# R7FA8M1AH register map
Vendor: Renesas; Series: RA8; File version: 1.2
CPU: CM85 r0p0, little endian, MPU, FPU, VTOR, 4 interrupt priority bits
Registers are 32-bit, read-write, reset 0x0 unless marked. A register's access mark holds for its fields unless they carry their own. Offsets are from the block's base; [hi:lo] are bit positions; {n}, {i} and the like mark numbered series; 'fields as' and 'values as' point back to an identical list.

## GPT320 (part 1 of 2) — General PWM 32-bit Timer 0
Base 0x40322000
Same registers: GPT321 0x40322100, GPT322 0x40322200, GPT323 0x40322300, GPT324 0x40322400, GPT325 0x40322500, GPT326 0x40322600, GPT327 0x40322700, GPT168 0x40322800, GPT169 0x40322900, GPT1610 0x40322A00, GPT1611 0x40322B00, GPT1612 0x40322C00, GPT1613 0x40322D00, GPT{n}_NS {0x5030E000+0x100*n} (n=320..327), GPT168_NS 0x50322800, GPT169_NS 0x50322900, GPT1610_NS 0x50322A00, GPT1611_NS 0x50322B00, GPT1612_NS 0x50322C00, GPT1613_NS 0x50322D00
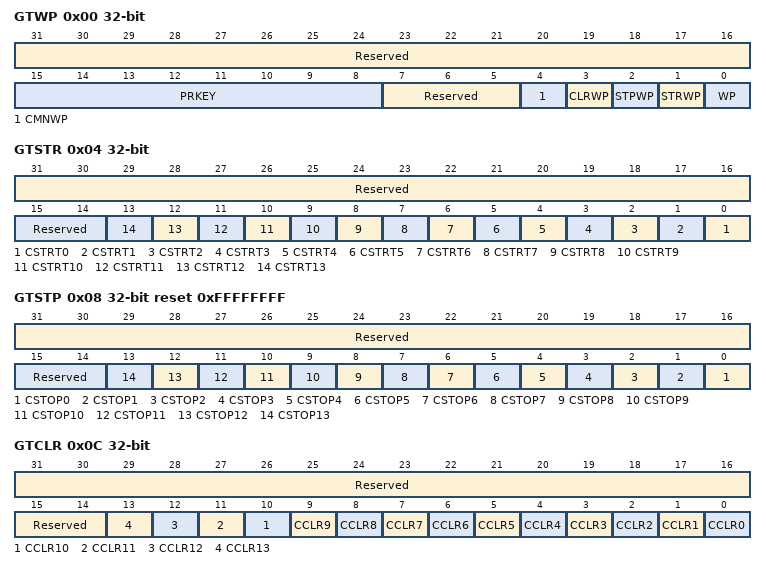
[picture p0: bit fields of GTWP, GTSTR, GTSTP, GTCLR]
0x00 GTWP — General PWM Timer Write-Protection Register
  [31:16] Reserved — These bits are read as 0000000000000000. The write value should be 0000000000000000.
  [15:8] PRKEY wo — GTWP Key Code
    165=Written to these bits, the WP bits write is permitted; other=others (The WP bits write is not permitted.)
  [7:5] Reserved — These bits are read as 000. The write value should be 000.
  [4] CMNWP — Common Register Write Disabled
    0=Write to the register is enabled; 1=Write to the register is disabled
  [3] CLRWP — GTCLR.CCLR Bit Write Disabled
    0=Write to the bit is enabled; 1=Write to the bit is disabled
  [2] STPWP — GTSTP.CSTOP Bit Write Disabled
    values as CLRWP
  [1] STRWP — GTSTR.CSTRT Bit Write Disabled
    values as CLRWP
  [0] WP — Register Write Disable
    0=Enable writes to the register; 1=Disable writes to the register
0x04 GTSTR — General PWM Timer Software Start Register
  [31:16] Reserved — These bits are read as 0000000000000000. The write value should be 0000000000000000.
  [15:14] Reserved — These bits are read as 00. The write value should be 00.
  [n] CSTRT{n} (n=0..13) — Channel {n} GTCNT Count StartRead data shows each channel's counter status (GTCR.CST bit). 0 means counter stop. 1 means counter running.
    0=No effect (write) / counter stop (read); 1=GTCNT counter starts (write) / Counter running (read)
0x08 GTSTP reset 0xFFFFFFFF — General PWM Timer Software Stop Register
  [31:16] Reserved — These bits are read as 1111111111111111. The write value should be 1111111111111111.
  [15:14] Reserved — These bits are read as 11. The write value should be 11.
  [n] CSTOP{n} (n=0..13) — Channel {n} GTCNT Count StopRead data shows each channel's counter status (GTCR.CST bit). 0 means counter runnning. 1 means counter stop.
    0=No effect (write) / counter running (read); 1=GTCNT counter stops (write) / Counter stop (read)
0x0C GTCLR wo — General PWM Timer Software Clear Register
  [31:14] Reserved — The write value should be 000000000000000000.
  [n] CCLR{n} (n=0..13) — Channel {n} GTCNT Count Clear
    0=No effect; 1=GTCNT counter clears
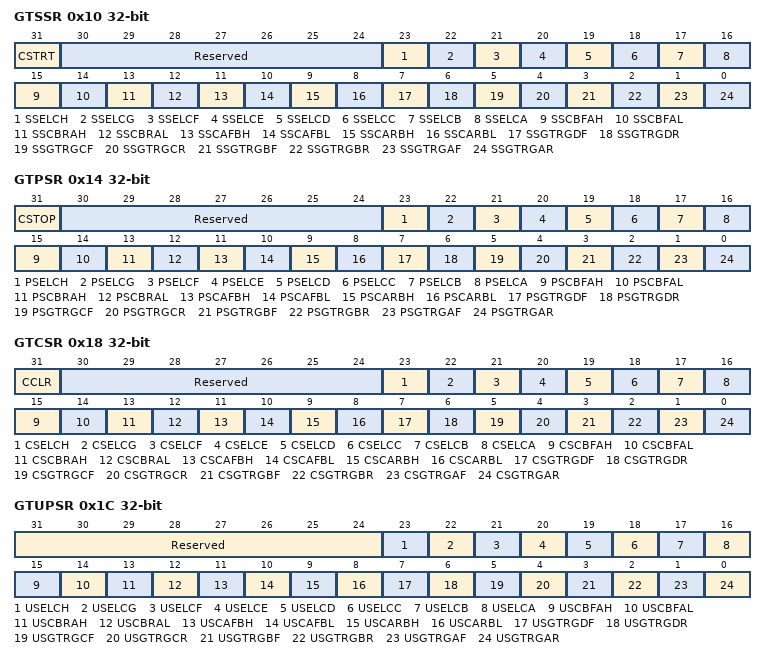
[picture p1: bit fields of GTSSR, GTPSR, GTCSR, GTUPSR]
0x10 GTSSR — General PWM Timer Start Source Select Register
  [31] CSTRT — Software Source Counter Start Enable
    0=Disable counter start by the GTSTR register; 1=Enable counter start by the GTSTR register
  [30:24] Reserved — These bits are read as 0000000. The write value should be 0000000.
  [23] SSELCH — ELC_GPTH Event Source Counter Start Enable
    0=Disable counter start on ELC_GPTH input; 1=Enable counter start on ELC_GPTH input
  [22] SSELCG — ELC_GPTG Event Source Counter Start Enable
    0=Disable counter start on ELC_GPTG input; 1=Enable counter start on ELC_GPTG input
  [21] SSELCF — ELC_GPTF Event Source Counter Start Enable
    0=Disable counter start on ELC_GPTF input; 1=Enable counter start on ELC_GPTF input
  [20] SSELCE — ELC_GPTE Event Source Counter Start Enable
    0=Disable counter start on ELC_GPTE input; 1=Enable counter start on ELC_GPTE input
  [19] SSELCD — ELC_GPTD Event Source Counter Start Enable
    0=Disable counter start on ELC_GPTD input; 1=Enable counter start on ELC_GPTD input
  [18] SSELCC — ELC_GPTC Event Source Counter Start Enable
    0=Disable counter start on ELC_GPTC input; 1=Enable counter start on ELC_GPTC input
  [17] SSELCB — ELC_GPTB Event Source Counter Start Enable
    0=Disable counter start on ELC_GPTB input; 1=Enable counter start on ELC_GPTB input
  [16] SSELCA — ELC_GPTA Event Source Counter Start Enable
    0=Disable counter start on ELC_GPTA input; 1=Enable counter start on ELC_GPTA input
  [15] SSCBFAH — GTIOCB Pin Falling Input during GTIOCA Value High Source Counter Start Enable
    0=Disable counter start on the falling edge of GTIOCB input when GTIOCA input is 1; 1=Enable counter start on the falling edge of GTIOCB input when GTIOCA input is 1
  [14] SSCBFAL — GTIOCB Pin Falling Input during GTIOCA Value Low Source Counter Start Enable
    0=Disable counter start on the falling edge of GTIOCB input when GTIOCA input is 0; 1=Enable counter start on the falling edge of GTIOCB input when GTIOCA input is 0
  [13] SSCBRAH — GTIOCB Pin Rising Input during GTIOCA Value High Source Counter Start Enable
    0=Disable counter start on the rising edge of GTIOCB input when GTIOCA input is 1; 1=Enable counter start on the rising edge of GTIOCB input when GTIOCA input is 1
  [12] SSCBRAL — GTIOCB Pin Rising Input during GTIOCA Value Low Source Counter Start Enable
    0=Disable counter start on the rising edge of GTIOCB input when GTIOCA input is 0; 1=Enable counter start on the rising edge of GTIOCB input when GTIOCA input is 0
  [11] SSCAFBH — GTIOCA Pin Falling Input during GTIOCB Value High Source Counter Start Enable
    0=Disable counter start on the falling edge of GTIOCA input when GTIOCB input is 1; 1=Enable counter start on the falling edge of GTIOCA input when GTIOCB input is 1
  [10] SSCAFBL — GTIOCA Pin Falling Input during GTIOCB Value Low Source Counter Start Enable
    0=Disable counter start on the falling edge of GTIOCA input when GTIOCB input is 0; 1=Enable counter start on the falling edge of GTIOCA input when GTIOCB input is 0
  [9] SSCARBH — GTIOCA Pin Rising Input during GTIOCB Value High Source Counter Start Enable
    0=Disable counter start on the rising edge of GTIOCA input when GTIOCB input is 1; 1=Enable counter start on the rising edge of GTIOCA input when GTIOCB input is 1
  [8] SSCARBL — GTIOCA Pin Rising Input during GTIOCB Value Low Source Counter Start Enable
    0=Disable counter start on the rising edge of GTIOCA input when GTIOCB input is 0; 1=Enable counter start on the rising edge of GTIOCA input when GTIOCB input is 0
  [7] SSGTRGDF — GTETRGD Pin Falling Input Source Counter Start Enable
    0=Disable counter start on the falling edge of GTETRGD input; 1=Enable counter start on the falling edge of GTETRGD input
  [6] SSGTRGDR — GTETRGD Pin Rising Input Source Counter Start Enable
    0=Disable counter start on the rising edge of GTETRGD input; 1=Enable counter start on the rising edge of GTETRGD input
  [5] SSGTRGCF — GTETRGC Pin Falling Input Source Counter Start Enable
    0=Disable counter start on the falling edge of GTETRGC input; 1=Enable counter start on the falling edge of GTETRGC input
  [4] SSGTRGCR — GTETRGC Pin Rising Input Source Counter Start Enable
    0=Disable counter start on the rising edge of GTETRGC input; 1=Enable counter start on the rising edge of GTETRGC input
  [3] SSGTRGBF — GTETRGB Pin Falling Input Source Counter Start Enable
    0=Disable counter start on the falling edge of GTETRGB input; 1=Enable counter start on the falling edge of GTETRGB input
  [2] SSGTRGBR — GTETRGB Pin Rising Input Source Counter Start Enable
    0=Disable counter start on the rising edge of GTETRGB input; 1=Enable counter start on the rising edge of GTETRGB input
  [1] SSGTRGAF — GTETRGA Pin Falling Input Source Counter Start Enable
    0=Disable counter start on the falling edge of GTETRGA input; 1=Enable counter start on the falling edge of GTETRGA input
  [0] SSGTRGAR — GTETRGA Pin Rising Input Source Counter Start Enable
    0=Disable counter start on the rising edge of GTETRGA input; 1=Enable counter start on the rising edge of GTETRGA input
0x14 GTPSR — General PWM Timer Stop Source Select Register
  [31] CSTOP — Software Source Counter Stop Enable
    0=Disable counter stop by the GTSTP register; 1=Enable counter stop by the GTSTP register
  [30:24] Reserved — These bits are read as 0000000. The write value should be 0000000.
  [23] PSELCH — ELC_GPTH Event Source Counter Stop Enable
    0=Disable counter stop on ELC_GPTH input; 1=Enable counter stop on ELC_GPTH input
  [22] PSELCG — ELC_GPTG Event Source Counter Stop Enable
    0=Disable counter stop on ELC_GPTG input; 1=Enable counter stop on ELC_GPTG input
  [21] PSELCF — ELC_GPTF Event Source Counter Stop Enable
    0=Disable counter stop on ELC_GPTF input; 1=Enable counter stop on ELC_GPTF input
  [20] PSELCE — ELC_GPTE Event Source Counter Stop Enable
    0=Disable counter stop on ELC_GPTE input; 1=Enable counter stop on ELC_GPTE input
  [19] PSELCD — ELC_GPTD Event Source Counter Stop Enable
    0=Disable counter stop on ELC_GPTD input; 1=Enable counter stop on ELC_GPTD input
  [18] PSELCC — ELC_GPTC Event Source Counter Stop Enable
    0=Disable counter stop on ELC_GPTC input; 1=Enable counter stop on ELC_GPTC input
  [17] PSELCB — ELC_GPTB Event Source Counter Stop Enable
    0=Disable counter stop on ELC_GPTB input; 1=Enable counter stop on ELC_GPTB input
  [16] PSELCA — ELC_GPTA Event Source Counter Stop Enable
    0=Disable counter stop on ELC_GPTA input; 1=Enable counter stop on ELC_GPTA input
  [15] PSCBFAH — GTIOCB Pin Falling Input during GTIOCA Value High Source Counter Stop Enable
    0=Disable counter stop on the falling edge of GTIOCB input when GTIOCA input is 1; 1=Enable counter stop on the falling edge of GTIOCB input when GTIOCA input is 1
  [14] PSCBFAL — GTIOCB Pin Falling Input during GTIOCA Value Low Source Counter Stop Enable
    0=Disable counter stop on the falling edge of GTIOCB input when GTIOCA input is 0; 1=Enable counter stop on the falling edge of GTIOCB input when GTIOCA input is 0
  [13] PSCBRAH — GTIOCB Pin Rising Input during GTIOCA Value High Source Counter Stop Enable
    0=Disable counter stop on the rising edge of GTIOCB input when GTIOCA input is 1; 1=Enable counter stop on the rising edge of GTIOCB input when GTIOCA input is 1
  [12] PSCBRAL — GTIOCB Pin Rising Input during GTIOCA Value Low Source Counter Stop Enable
    0=Disable counter stop on the rising edge of GTIOCB input when GTIOCA input is 0; 1=Enable counter stop on the rising edge of GTIOCB input when GTIOCA input is 0
  [11] PSCAFBH — GTIOCA Pin Falling Input during GTIOCB Value High Source Counter Stop Enable
    0=Disable counter stop on the falling edge of GTIOCA input when GTIOCB input is 1; 1=Enable counter stop on the falling edge of GTIOCA input when GTIOCB input is 1
  [10] PSCAFBL — GTIOCA Pin Falling Input during GTIOCB Value Low Source Counter Stop Enable
    0=Disable counter stop on the falling edge of GTIOCA input when GTIOCB input is 0; 1=Enable counter stop on the falling edge of GTIOCA input when GTIOCB input is 0
  [9] PSCARBH — GTIOCA Pin Rising Input during GTIOCB Value High Source Counter Stop Enable
    0=Disable counter stop on the rising edge of GTIOCA input when GTIOCB input is 1; 1=Enable counter stop on the rising edge of GTIOCA input when GTIOCB input is 1
  [8] PSCARBL — GTIOCA Pin Rising Input during GTIOCB Value Low Source Counter Stop Enable
    0=Disable counter stop on the rising edge of GTIOCA input when GTIOCB input is 0; 1=Enable counter stop on the rising edge of GTIOCA input when GTIOCB input is 0
  [7] PSGTRGDF — GTETRGD Pin Falling Input Source Counter Stop Enable
    0=Disable counter stop on the falling edge of GTETRGD input; 1=Enable counter stop on the falling edge of GTETRGD input
  [6] PSGTRGDR — GTETRGD Pin Rising Input Source Counter Stop Enable
    0=Disable counter stop on the rising edge of GTETRGD input; 1=Enable counter stop on the rising edge of GTETRGD input
  [5] PSGTRGCF — GTETRGC Pin Falling Input Source Counter Stop Enable
    0=Disable counter stop on the falling edge of GTETRGC input; 1=Enable counter stop on the falling edge of GTETRGC input
  [4] PSGTRGCR — GTETRGC Pin Rising Input Source Counter Stop Enable
    0=Disable counter stop on the rising edge of GTETRGC input; 1=Enable counter stop on the rising edge of GTETRGC input
  [3] PSGTRGBF — GTETRGB Pin Falling Input Source Counter Stop Enable
    0=Disable counter stop on the falling edge of GTETRGB input; 1=Enable counter stop on the falling edge of GTETRGB input
  [2] PSGTRGBR — GTETRGB Pin Rising Input Source Counter Stop Enable
    0=Disable counter stop on the rising edge of GTETRGB input; 1=Enable counter stop on the rising edge of GTETRGB input
  [1] PSGTRGAF — GTETRGA Pin Falling Input Source Counter Stop Enable
    0=Disable counter stop on the falling edge of GTETRGA input; 1=Enable counter stop on the falling edge of GTETRGA input
  [0] PSGTRGAR — GTETRGA Pin Rising Input Source Counter Stop Enable
    0=Disable counter stop on the rising edge of GTETRGA input; 1=Enable counter stop on the rising edge of GTETRGA input
0x18 GTCSR — General PWM Timer Clear Source Select Register
  [31] CCLR — Software Source Counter Clear Enable
    0=Disable counter clear by the GTCLR register; 1=Enable counter clear by the GTCLR register
  [30:24] Reserved — These bits are read as 0000000. The write value should be 0000000.
  [23] CSELCH — ELC_GPTH Event Source Counter Clear Enable
    0=Disable counter clear on ELC_GPTH input; 1=Enable counter clear on ELC_GPTH input
  [22] CSELCG — ELC_GPTG Event Source Counter Clear Enable
    0=Disable counter clear on ELC_GPTG input; 1=Enable counter clear on ELC_GPTG input
  [21] CSELCF — ELC_GPTF Event Source Counter Clear Enable
    0=Disable counter clear on ELC_GPTF input; 1=Enable counter clear on ELC_GPTF input
  [20] CSELCE — ELC_GPTE Event Source Counter Clear Enable
    0=Disable counter clear on ELC_GPTE input; 1=Enable counter clear on ELC_GPTE input
  [19] CSELCD — ELC_GPTD Event Source Counter Clear Enable
    0=Disable counter clear on ELC_GPTD input; 1=Enable counter clear on ELC_GPTD input
  [18] CSELCC — ELC_GPTC Event Source Counter Clear Enable
    0=Disable counter clear on ELC_GPTC input; 1=Enable counter clear on ELC_GPTC input
  [17] CSELCB — ELC_GPTB Event Source Counter Clear Enable
    0=Disable counter clear on ELC_GPTB input; 1=Enable counter clear on ELC_GPTB input
  [16] CSELCA — ELC_GPTA Event Source Counter Clear Enable
    0=Disable counter clear on ELC_GPTA input; 1=Enable counter clear on ELC_GPTA input
  [15] CSCBFAH — GTIOCB Pin Falling Input during GTIOCA Value High Source Counter Clear Enable
    0=Disable counter clear on the falling edge of GTIOCB input when GTIOCA input is 1; 1=Enable counter clear on the falling edge of GTIOCB input when GTIOCA input is 1
  [14] CSCBFAL — GTIOCB Pin Falling Input during GTIOCA Value Low Source Counter Clear Enable
    0=Disable counter clear on the falling edge of GTIOCB input when GTIOCA input is 0; 1=Enable counter clear on the falling edge of GTIOCB input when GTIOCA input is 0
  [13] CSCBRAH — GTIOCB Pin Rising Input during GTIOCA Value High Source Counter Clear Enable
    0=Disable counter clear on the rising edge of GTIOCB input when GTIOCA input is 1; 1=Enable counter clear on the rising edge of GTIOCB input when GTIOCA input is 1
  [12] CSCBRAL — GTIOCB Pin Rising Input during GTIOCA Value Low Source Counter Clear Enable
    0=Disable counter clear on the rising edge of GTIOCB input when GTIOCA input is 0; 1=Enable counter clear on the rising edge of GTIOCB input when GTIOCA input is 0
  [11] CSCAFBH — GTIOCA Pin Falling Input during GTIOCB Value High Source Counter Clear Enable
    0=Disable counter clear on the falling edge of GTIOCA input when GTIOCB input is 1; 1=Enable counter clear on the falling edge of GTIOCA input when GTIOCB input is 1
  [10] CSCAFBL — GTIOCA Pin Falling Input during GTIOCB Value Low Source Counter Clear Enable
    0=Disable counter clear on the falling edge of GTIOCA input when GTIOCB input is 0; 1=Enable counter clear on the falling edge of GTIOCA input when GTIOCB input is 0
  [9] CSCARBH — GTIOCA Pin Rising Input during GTIOCB Value High Source Counter Clear Enable
    0=Disable counter clear on the rising edge of GTIOCA input when GTIOCB input is 1; 1=Enable counter clear on the rising edge of GTIOCA input when GTIOCB input is 1
  [8] CSCARBL — GTIOCA Pin Rising Input during GTIOCB Value Low Source Counter Clear Enable
    0=Disable counter clear on the rising edge of GTIOCA input when GTIOCB input is 0; 1=Enable counter clear on the rising edge of GTIOCA input when GTIOCB input is 0
  [7] CSGTRGDF — GTETRGD Pin Falling Input Source Counter Clear Enable
    0=Disable counter clear on the falling edge of GTETRGD input; 1=Enable counter clear on the falling edge of GTETRGD input
  [6] CSGTRGDR — GTETRGD Pin Rising Input Source Counter Clear Enable
    0=Disable counter clear on the rising edge of GTETRGD input; 1=Enable counter clear on the rising edge of GTETRGD input
  [5] CSGTRGCF — GTETRGC Pin Falling Input Source Counter Clear Enable
    0=Disable counter clear on the falling edge of GTETRGC input; 1=Enable counter clear on the falling edge of GTETRGC input
  [4] CSGTRGCR — GTETRGC Pin Rising Input Source Counter Clear Enable
    0=Disable counter clear on the rising edge of GTETRGC input; 1=Enable counter clear on the rising edge of GTETRGC input
  [3] CSGTRGBF — GTETRGB Pin Falling Input Source Counter Clear Enable
    0=Disable counter clear on the falling edge of GTETRGB input; 1=Enable counter clear on the falling edge of GTETRGB input
  [2] CSGTRGBR — GTETRGB Pin Rising Input Source Counter Clear Enable
    0=Disable counter clear on the rising edge of GTETRGB input; 1=Enable counter clear on the rising edge of GTETRGB input
  [1] CSGTRGAF — GTETRGA Pin Falling Input Source Counter Clear Enable
    0=Disable counter clear on the falling edge of GTETRGA input; 1=Enable counter clear on the falling edge of GTETRGA input
  [0] CSGTRGAR — GTETRGA Pin Rising Input Source Counter Clear Enable
    0=Disable counter clear on the rising edge of GTETRGA input; 1=Enable counter clear on the rising edge of GTETRGA input
0x1C GTUPSR — General PWM Timer Up Count Source Select Register
  [31:24] Reserved — These bits are read as 00000000. The write value should be 00000000.
  [23] USELCH — ELC_GPTH Event Source Counter Count Up Enable
    0=Disable counter count up on ELC_GPTH input; 1=Enable counter count up on ELC_GPTH input
  [22] USELCG — ELC_GPTG Event Source Counter Count Up Enable
    0=Disable counter count up on ELC_GPTG input; 1=Enable counter count up on ELC_GPTG input
  [21] USELCF — ELC_GPTF Event Source Counter Count Up Enable
    0=Disable counter count up on ELC_GPTF input; 1=Enable counter count up on ELC_GPTF input
  [20] USELCE — ELC_GPTE Event Source Counter Count Up Enable
    0=Disable counter count up on ELC_GPTE input; 1=Enable counter count up on ELC_GPTE input.put
  [19] USELCD — ELC_GPTD Event Source Counter Count Up Enable
    0=Disable counter count up on ELC_GPTD input; 1=Enable counter count up on ELC_GPTD input
  [18] USELCC — ELC_GPTC Event Source Counter Count Up Enable
    0=Disable counter count up on ELC_GPTC input; 1=Enable counter count up on ELC_GPTC input
  [17] USELCB — ELC_GPTB Event Source Counter Count Up Enable
    0=Disable counter count up on ELC_GPTB input; 1=Enable counter count up on ELC_GPTB input
  [16] USELCA — ELC_GPTA Event Source Counter Count Up Enable
    0=Disable counter count up on ELC_GPTA input; 1=Enable counter count up on ELC_GPTA input
  [15] USCBFAH — GTIOCB Pin Falling Input during GTIOCA Value High Source Counter Count Up Enable
    0=Disable counter count up on the falling edge of GTIOCB input when GTIOCA input is 1; 1=Enable counter count up on the falling edge of GTIOCB input when GTIOCA input is 1
  [14] USCBFAL — GTIOCB Pin Falling Input during GTIOCA Value Low Source Counter Count Up Enable
    0=Disable counter count up on the falling edge of GTIOCB input when GTIOCA input is 0; 1=Enable counter count up on the falling edge of GTIOCB input when GTIOCA input is 0
  [13] USCBRAH — GTIOCB Pin Rising Input during GTIOCA Value High Source Counter Count Up Enable
    0=Disable counter count up on the rising edge of GTIOCB input when GTIOCA input is 1; 1=Enable counter count up on the rising edge of GTIOCB input when GTIOCA input is 1
  [12] USCBRAL — GTIOCB Pin Rising Input during GTIOCA Value Low Source Counter Count Up Enable
    0=Disable counter count up on the rising edge of GTIOCB input when GTIOCA input is 0; 1=Enable counter count up on the rising edge of GTIOCB input when GTIOCA input is 0
  [11] USCAFBH — GTIOCA Pin Falling Input during GTIOCB Value High Source Counter Count Up Enable
    0=Disable counter count up on the falling edge of GTIOCA input when GTIOCB input is 1; 1=Enable counter count up on the falling edge of GTIOCA input when GTIOCB input is 1
  [10] USCAFBL — GTIOCA Pin Falling Input during GTIOCB Value Low Source Counter Count Up Enable
    0=Disable counter count up on the falling edge of GTIOCA input when GTIOCB input is 0; 1=Enable counter count up on the falling edge of GTIOCA input when GTIOCB input is 0
  [9] USCARBH — GTIOCA Pin Rising Input during GTIOCB Value High Source Counter Count Up Enable
    0=Disable counter count up on the rising edge of GTIOCA input when GTIOCB input is 1; 1=Enable counter count up on the rising edge of GTIOCA input when GTIOCB input is 1
  [8] USCARBL — GTIOCA Pin Rising Input during GTIOCB Value Low Source Counter Count Up Enable
    0=Disable counter count up on the rising edge of GTIOCA input when GTIOCB input is 0; 1=Enable counter count up on the rising edge of GTIOCA input when GTIOCB input is 0
  [7] USGTRGDF — GTETRGD Pin Falling Input Source Counter Count Up Enable
    0=Disable counter count up on the falling edge of GTETRGD input; 1=Enable counter count up on the falling edge of GTETRGD input
  [6] USGTRGDR — GTETRGD Pin Rising Input Source Counter Count Up Enable
    0=Disable counter count up on the rising edge of GTETRGD input; 1=Enable counter count up on the rising edge of GTETRGD input
  [5] USGTRGCF — GTETRGC Pin Falling Input Source Counter Count Up Enable
    0=Disable counter count up on the falling edge of GTETRGC input; 1=Enable counter count up on the falling edge of GTETRGC input
  [4] USGTRGCR — GTETRGC Pin Rising Input Source Counter Count Up Enable
    0=Disable counter count up on the rising edge of GTETRGC input; 1=Enable counter count up on the rising edge of GTETRGC input
  [3] USGTRGBF — GTETRGB Pin Falling Input Source Counter Count Up Enable
    0=Disable counter count up on the falling edge of GTETRGB input; 1=Enable counter count up on the falling edge of GTETRGB input
  [2] USGTRGBR — GTETRGB Pin Rising Input Source Counter Count Up Enable
    0=Disable counter count up on the rising edge of GTETRGB input; 1=Enable counter count up on the rising edge of GTETRGB input
  [1] USGTRGAF — GTETRGA Pin Falling Input Source Counter Count Up Enable
    0=Disable counter count up on the falling edge of GTETRGA input; 1=Enable counter count up on the falling edge of GTETRGA input
  [0] USGTRGAR — GTETRGA Pin Rising Input Source Counter Count Up Enable
    0=Disable counter count up on the rising edge of GTETRGA input; 1=Enable counter count up on the rising edge of GTETRGA input
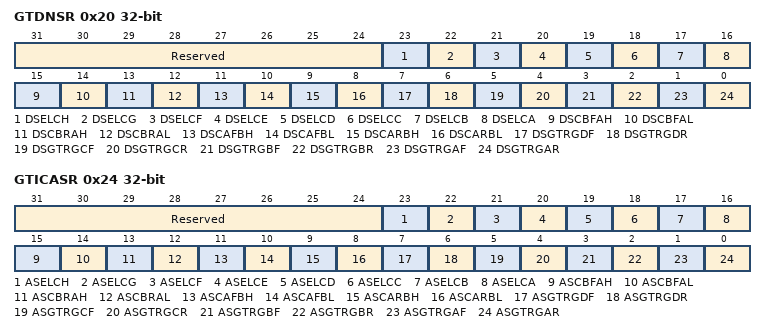
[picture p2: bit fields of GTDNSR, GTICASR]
0x20 GTDNSR — General PWM Timer Down Count Source Select Register
  [31:24] Reserved — These bits are read as 00000000. The write value should be 00000000.
  [23] DSELCH — ELC_GPTH Event Source Counter Count Down Enable
    0=Disable counter count down on ELC_GPTH input; 1=Enable counter count down on ELC_GPTH input
  [22] DSELCG — ELC_GPTG Event Source Counter Count Down Enable
    0=Disable counter count down on ELC_GPTG input; 1=Enable counter count down on ELC_GPTG input
  [21] DSELCF — ELC_GPTF Event Source Counter Count Down Enable
    0=Disable counter count down on ELC_GPTF input; 1=Enable counter count down on ELC_GPTF input
  [20] DSELCE — ELC_GPTE Event Source Counter Count Down Enable
    0=Disable counter count down on ELC_GPTE input; 1=Enable counter count down on ELC_GPTE input
  [19] DSELCD — ELC_GPTD Event Source Counter Count Down Enable
    0=Disable counter count down on ELC_GPTD input; 1=Enable counter count down on ELC_GPTD input
  [18] DSELCC — ELC_GPTC Event Source Counter Count Down Enable
    0=Disable counter count down on ELC_GPTC input; 1=Enable counter count down on ELC_GPTC input
  [17] DSELCB — ELC_GPTB Event Source Counter Count Down Enable
    0=Disable counter count down on ELC_GPTB input; 1=Enable counter count down on ELC_GPTB input
  [16] DSELCA — ELC_GPTA Event Source Counter Count Down Enable
    0=Disable counter count down on ELC_GPTA input; 1=Enable counter count down on ELC_GPTA input
  [15] DSCBFAH — GTIOCB Pin Falling Input during GTIOCA Value High Source Counter Count Down Enable
    0=Disable counter count down on the falling edge of GTIOCB input when GTIOCA input is 1; 1=Enable counter count down on the falling edge of GTIOCB input when GTIOCA input is 1
  [14] DSCBFAL — GTIOCB Pin Falling Input during GTIOCA Value Low Source Counter Count Down Enable
    0=Disable counter count down on the falling edge of GTIOCB input when GTIOCA input is 0; 1=Enable counter count down on the falling edge of GTIOCB input when GTIOCA input is 0
  [13] DSCBRAH — GTIOCB Pin Rising Input during GTIOCA Value High Source Counter Count Down Enable
    0=Disable counter count down on the rising edge of GTIOCB input when GTIOCA input is 1; 1=Enable counter count down on the rising edge of GTIOCB input when GTIOCA input is 1
  [12] DSCBRAL — GTIOCB Pin Rising Input during GTIOCA Value Low Source Counter Count Down Enable
    0=Disable counter count down on the rising edge of GTIOCB input when GTIOCA input is 0; 1=Enable counter count down on the rising edge of GTIOCB input when GTIOCA input is 0
  [11] DSCAFBH — GTIOCA Pin Falling Input during GTIOCB Value High Source Counter Count Down Enable
    0=Disable counter count down on the falling edge of GTIOCA input when GTIOCB input is 1; 1=Enable counter count down on the falling edge of GTIOCA input when GTIOCB input is 1
  [10] DSCAFBL — GTIOCA Pin Falling Input during GTIOCB Value Low Source Counter Count Down Enable
    0=Disable counter count down on the falling edge of GTIOCA input when GTIOCB input is 0; 1=Enable counter count down on the falling edge of GTIOCA input when GTIOCB input is 0
  [9] DSCARBH — GTIOCA Pin Rising Input during GTIOCB Value High Source Counter Count Down Enable
    0=Disable counter count down on the rising edge of GTIOCA input when GTIOCB input is 1; 1=Enable counter count down on the rising edge of GTIOCA input when GTIOCB input is 1
  [8] DSCARBL — GTIOCA Pin Rising Input during GTIOCB Value Low Source Counter Count Down Enable
    0=Disable counter count down on the rising edge of GTIOCA input when GTIOCB input is 0; 1=Enable counter count down on the rising edge of GTIOCA input when GTIOCB input is 0
  [7] DSGTRGDF — GTETRGD Pin Falling Input Source Counter Count Down Enable
    0=Disable counter count down on the falling edge of GTETRGD input; 1=Enable counter count down on the falling edge of GTETRGD input
  [6] DSGTRGDR — GTETRGD Pin Rising Input Source Counter Count Down Enable
    0=Disable counter count down on the rising edge of GTETRGD input; 1=Enable counter count down on the rising edge of GTETRGD input
  [5] DSGTRGCF — GTETRGC Pin Falling Input Source Counter Count Down Enable
    0=Disable counter count down on the falling edge of GTETRGC input; 1=Enable counter count down on the falling edge of GTETRGC input
  [4] DSGTRGCR — GTETRGC Pin Rising Input Source Counter Count Down Enable
    0=Disable counter count down on the rising edge of GTETRGC input; 1=Enable counter count down on the rising edge of GTETRGC input
  [3] DSGTRGBF — GTETRGB Pin Falling Input Source Counter Count Down Enable
    0=Disable counter count down on the falling edge of GTETRGB input; 1=Enable counter count down on the falling edge of GTETRGB input
  [2] DSGTRGBR — GTETRGB Pin Rising Input Source Counter Count Down Enable
    0=Disable counter count down on the rising edge of GTETRGB input; 1=Enable counter count down on the rising edge of GTETRGB input
  [1] DSGTRGAF — GTETRGA Pin Falling Input Source Counter Count Down Enable
    0=Disable counter count down on the falling edge of GTETRGA input; 1=Enable counter count down on the falling edge of GTETRGA input
  [0] DSGTRGAR — GTETRGA Pin Rising Input Source Counter Count Down Enable
    0=Disable counter count down on the rising edge of GTETRGA input; 1=Enable counter count down on the rising edge of GTETRGA input
0x24 GTICASR — General PWM Timer Input Capture Source Select Register A
  [31:24] Reserved — These bits are read as 00000000. The write value should be 00000000.
  [23] ASELCH — ELC_GPTH Event Source GTCCRA Input Capture Enable
    0=Disable GTCCRA input capture on ELC_GPTH input; 1=Enable GTCCRA input capture on ELC_GPTH input
  [22] ASELCG — ELC_GPTG Event Source GTCCRA Input Capture Enable
    0=Disable GTCCRA input capture on ELC_GPTG input; 1=Enable GTCCRA input capture on ELC_GPTG input
  [21] ASELCF — ELC_GPTF Event Source GTCCRA Input Capture Enable
    0=Disable GTCCRA input capture on ELC_GPTF input; 1=Enable GTCCRA input capture on ELC_GPTF input
  [20] ASELCE — ELC_GPTE Event Source GTCCRA Input Capture Enable
    0=Disable GTCCRA input capture on ELC_GPTE input; 1=Enable GTCCRA input capture on ELC_GPTE input
  [19] ASELCD — ELC_GPTD Event Source GTCCRA Input Capture Enable
    0=Disable GTCCRA input capture on ELC_GPTD input; 1=Enable GTCCRA input capture on ELC_GPTD input
  [18] ASELCC — ELC_GPTC Event Source GTCCRA Input Capture Enable
    0=Disable GTCCRA input capture on ELC_GPTC input; 1=Enable GTCCRA input capture on ELC_GPTC input
  [17] ASELCB — ELC_GPTB Event Source GTCCRA Input Capture Enable
    0=Disable GTCCRA input capture on ELC_GPTB input; 1=Enable GTCCRA input capture on ELC_GPTB input
  [16] ASELCA — ELC_GPTA Event Source GTCCRA Input Capture Enable
    0=Disable GTCCRA input capture on ELC_GPTA input; 1=Enable GTCCRA input capture on ELC_GPTA input
  [15] ASCBFAH — GTIOCB Pin Falling Input during GTIOCA Value High Source GTCCRA Input Capture Enable
    0=Disable GTCCRA input capture on the falling edge of GTIOCB input when GTIOCA input is 1; 1=Enable GTCCRA input capture on the falling edge of GTIOCB input when GTIOCA input is 1
  [14] ASCBFAL — GTIOCB Pin Falling Input during GTIOCA Value Low Source GTCCRA Input Capture Enable
    0=Disable GTCCRA input capture on the falling edge of GTIOCB input when GTIOCA input is 0; 1=Enable GTCCRA input capture on the falling edge of GTIOCB input when GTIOCA input is 0
  [13] ASCBRAH — GTIOCB Pin Rising Input during GTIOCA Value High Source GTCCRA Input Capture Enable
    0=Disable GTCCRA input capture on the rising edge of GTIOCB input when GTIOCA input is 1; 1=Enable GTCCRA input capture on the rising edge of GTIOCB input when GTIOCA input is 1
  [12] ASCBRAL — GTIOCB Pin Rising Input during GTIOCA Value Low Source GTCCRA Input Capture Enable
    0=Disable GTCCRA input capture on the rising edge of GTIOCB input when GTIOCA input is 0; 1=Enable GTCCRA input capture on the rising edge of GTIOCB input when GTIOCA input is 0
  [11] ASCAFBH — GTIOCA Pin Falling Input during GTIOCB Value High Source GTCCRA Input Capture Enable
    0=Disable GTCCRA input capture on the falling edge of GTIOCA input when GTIOCB input is 1; 1=Enable GTCCRA input capture on the falling edge of GTIOCA input when GTIOCB input is 1
  [10] ASCAFBL — GTIOCA Pin Falling Input during GTIOCB Value Low Source GTCCRA Input Capture Enable
    0=Disable GTCCRA input capture on the falling edge of GTIOCA input when GTIOCB input is 0; 1=Enable GTCCRA input capture on the falling edge of GTIOCA input when GTIOCB input is 0
  [9] ASCARBH — GTIOCA Pin Rising Input during GTIOCB Value High Source GTCCRA Input Capture Enable
    0=Disable GTCCRA input capture on the rising edge of GTIOCA input when GTIOCB input is 1; 1=Enable GTCCRA input capture on the rising edge of GTIOCA input when GTIOCB input is 1
  [8] ASCARBL — GTIOCA Pin Rising Input during GTIOCB Value Low Source GTCCRA Input Capture Enable
    0=Disable GTCCRA input capture on the rising edge of GTIOCA input when GTIOCB input is 0; 1=Enable GTCCRA input capture on the rising edge of GTIOCA input when GTIOCB input is 0
  [7] ASGTRGDF — GTETRGD Pin Falling Input Source GTCCRA Input Capture Enable
    0=Disable GTCCRA input capture on the falling edge of GTETRGD input; 1=Enable GTCCRA input capture on the falling edge of GTETRGD input
  [6] ASGTRGDR — GTETRGD Pin Rising Input Source GTCCRA Input Capture Enable
    0=Disable GTCCRA input capture on the rising edge of GTETRGD input; 1=Enable GTCCRA input capture on the rising edge of GTETRGD input
  [5] ASGTRGCF — GTETRGC Pin Falling Input Source GTCCRA Input Capture Enable
    0=Disable GTCCRA input capture on the falling edge of GTETRGC input; 1=Enable GTCCRA input capture on the falling edge of GTETRGC input
  [4] ASGTRGCR — GTETRGC Pin Rising Input Source GTCCRA Input Capture Enable
    0=Disable GTCCRA input capture on the rising edge of GTETRGC input; 1=Enable GTCCRA input capture on the rising edge of GTETRGC input
  [3] ASGTRGBF — GTETRGB Pin Falling Input Source GTCCRA Input Capture Enable
    0=Disable GTCCRA input capture on the falling edge of GTETRGB input; 1=Enable GTCCRA input capture on the falling edge of GTETRGB input
  [2] ASGTRGBR — GTETRGB Pin Rising Input Source GTCCRA Input Capture Enable
    0=Disable GTCCRA input capture on the rising edge of GTETRGB input; 1=Enable GTCCRA input capture on the rising edge of GTETRGB input
  [1] ASGTRGAF — GTETRGA Pin Falling Input Source GTCCRA Input Capture Enable
    0=Disable GTCCRA input capture on the falling edge of GTETRGA input; 1=Enable GTCCRA input capture on the falling edge of GTETRGA input
  [0] ASGTRGAR — GTETRGA Pin Rising Input Source GTCCRA Input Capture Enable
    0=Disable GTCCRA input capture on the rising edge of GTETRGA input; 1=Enable GTCCRA input capture on the rising edge of GTETRGA input
